VERSION ""

NS_ :

BS_:

BU_: CAN_NODE1

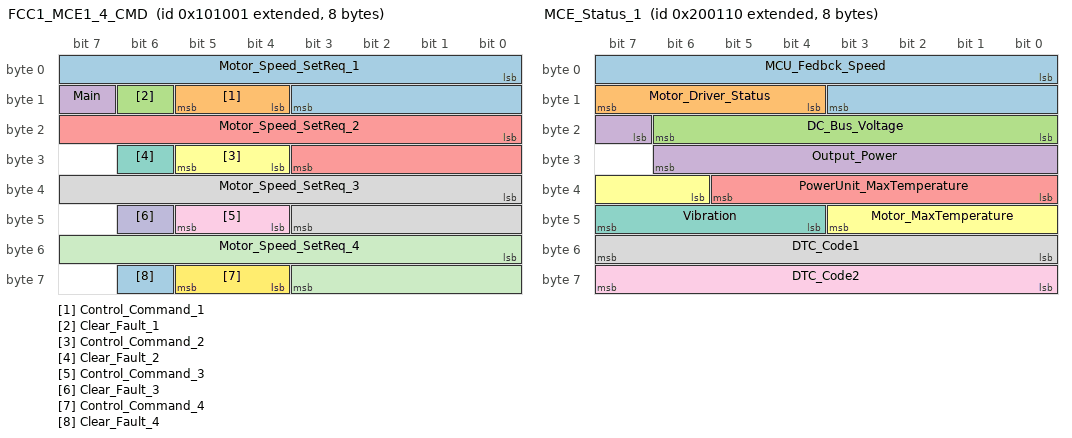
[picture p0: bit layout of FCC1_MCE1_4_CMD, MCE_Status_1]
BO_ 2148536321 FCC1_MCE1_4_CMD: 8 CAN_NODE1
	SG_ Motor_Speed_SetReq_1 : 0|12@1+ (2,0) [0|8190] "rpm" CAN_NODE1
	SG_ Control_Command_1 : 12|2@1+ (1,0) [0|2] "" CAN_NODE1
	SG_ Clear_Fault_1 : 14|1@1+ (1,0) [0|1] "" CAN_NODE1
	SG_ Main : 15|1@1+ (1,0) [0|1] "" CAN_NODE1
	SG_ Motor_Speed_SetReq_2 : 16|12@1+ (2,0) [0|8190] "rpm" CAN_NODE1
	SG_ Control_Command_2 : 28|2@1+ (1,0) [0|2] "" CAN_NODE1
	SG_ Clear_Fault_2 : 30|1@1+ (1,0) [0|1] "" CAN_NODE1
	SG_ Motor_Speed_SetReq_3 : 32|12@1+ (2,0) [0|8190] "rpm" CAN_NODE1
	SG_ Control_Command_3 : 44|2@1+ (1,0) [0|2] "" CAN_NODE1
	SG_ Clear_Fault_3 : 46|1@1+ (1,0) [0|1] "" CAN_NODE1
	SG_ Motor_Speed_SetReq_4 : 48|12@1+ (2,0) [0|8190] "rpm" CAN_NODE1
	SG_ Control_Command_4 : 60|2@1+ (1,0) [0|2] "" CAN_NODE1
	SG_ Clear_Fault_4 : 62|1@1+ (1,0) [0|1] "" CAN_NODE1

BO_ 2149581072 MCE_Status_1: 8 CAN_NODE1
	SG_ MCU_Fedbck_Speed : 0|12@1+ (2,0) [0|8190] "rpm" CAN_NODE1
	SG_ Motor_Driver_Status : 12|4@1+ (1,0) [0|15] "" CAN_NODE1
	SG_ DC_Bus_Voltage : 16|7@1+ (10,0) [0|1270] "V" CAN_NODE1
	SG_ Output_Power : 23|8@1+ (1,0) [0|255] "kW" CAN_NODE1
	SG_ PowerUnit_MaxTemperature : 32|6@1+ (4,-40) [-40|215] "degC" CAN_NODE1
	SG_ Motor_MaxTemperature : 38|6@1+ (4,-40) [-40|215] "degC" CAN_NODE1
	SG_ Vibration : 44|4@1+ (2,0) [0|31] "g" CAN_NODE1
	SG_ DTC_Code1 : 48|8@1+ (1,0) [0|255] "" CAN_NODE1
	SG_ DTC_Code2 : 56|8@1+ (1,0) [0|255] "" CAN_NODE1

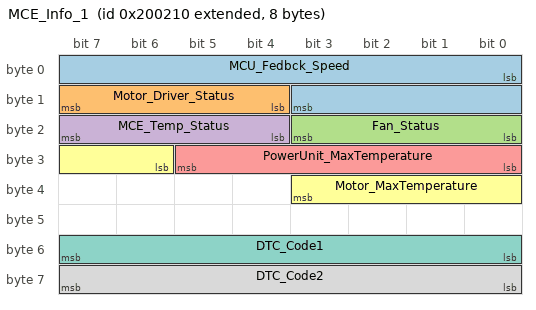
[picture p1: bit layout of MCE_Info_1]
BO_ 2149581328 MCE_Info_1: 8 CAN_NODE1
	SG_ MCU_Fedbck_Speed : 0|12@1+ (2,0) [0|8190] "rpm" CAN_NODE1
	SG_ Motor_Driver_Status : 12|4@1+ (1,0) [0|15] "" CAN_NODE1
	SG_ Fan_Status : 16|4@1+ (1,0) [0|15] "" CAN_NODE1
	SG_ MCE_Temp_Status : 20|4@1+ (1,0) [0|15] "" CAN_NODE1
	SG_ PowerUnit_MaxTemperature : 24|6@1+ (4,-40) [-40|215] "degC" CAN_NODE1
	SG_ Motor_MaxTemperature : 30|6@1+ (4,-40) [-40|215] "degC" CAN_NODE1
	SG_ DTC_Code1 : 48|8@1+ (1,0) [0|255] "" CAN_NODE1
	SG_ DTC_Code2 : 56|8@1+ (1,0) [0|255] "" CAN_NODE1

CM_ BO_ 2148536321 "FCC1_MCE1_4_CMD";
CM_ SG_ 2148536321 Motor_Speed_SetReq_1 "设定转速";
CM_ SG_ 2148536321 Control_Command_1 "电机1控制模式：0=待机 1=运行 2=应急停车 3=空指令";
CM_ SG_ 2148536321 Clear_Fault_1 "清除电机1故障标志：1=清除";
CM_ SG_ 2148536321 Main "主飞控信号标识位";
CM_ BO_ 2149581072 "MCE 1-10";
CM_ SG_ 2149581072 MCU_Fedbck_Speed "电机运行转速";
CM_ SG_ 2149581072 Motor_Driver_Status "电机系统运行状态";
CM_ SG_ 2149581072 DC_Bus_Voltage "母线电压";
CM_ SG_ 2149581072 Output_Power "电机转矩 / 输出功率（以电磁转矩，机械转速进行计算）";
CM_ SG_ 2149581072 PowerUnit_MaxTemperature "功率模块最高温度点";
CM_ SG_ 2149581072 Motor_MaxTemperature "电机最高温度点";
CM_ SG_ 2149581072 Vibration "电机系统振动";
CM_ SG_ 2149581072 DTC_Code1 "故障码1 (见DTC_Codes1解析表)";
CM_ SG_ 2149581072 DTC_Code2 "故障码2 (见DTC_Codes2解析表)";
CM_ BO_ 2149581328 "指示记录系统";
CM_ SG_ 2149581328 MCU_Fedbck_Speed "电机运行转速";
CM_ SG_ 2149581328 Motor_Driver_Status "电机系统运行状态";
CM_ SG_ 2149581328 PowerUnit_MaxTemperature "功率模块最高温度点";
CM_ SG_ 2149581328 Motor_MaxTemperature "电机最高温度点";
CM_ SG_ 2149581328 DTC_Code1 "故障码1 (见DTC_Codes1解析表)";
CM_ SG_ 2149581328 DTC_Code2 "故障码2 (见DTC_Codes2解析表)";

// === 波特率配置 ===
BA_DEF_ BU_  "Baudrate" INT 0 2000000;
BA_DEF_DEF_  "Baudrate" 500000;
